AUTOSAR XML (schema 00046)
package /Composit_SW_Lab
  sender receiver interface SRIF_LightControl
    data Light_Control: type=uint32
  sender receiver interface SRIF_LightActuate
    data Light_Actuate: type=uint32
  sensor actuator sw component type LightControl_SWC
    provide port PP_LightControl: provided-interface=SRIF_LightControl
  sensor actuator sw component type LightActuate_SWC
    require port RP_LightActuate: required-interface=SRIF_LightActuate
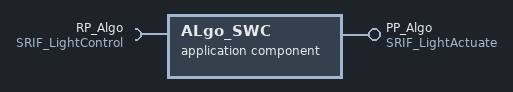
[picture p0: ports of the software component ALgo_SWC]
  application sw component type ALgo_SWC
    provide port PP_Algo: provided-interface=SRIF_LightActuate
    require port RP_Algo: required-interface=SRIF_LightControl
  composition sw component type Composite_SWC1
    provide port PP_Algo_Comp: provided-interface=SRIF_LightActuate
    component SA_LC_SWC: type=LightControl_SWC
    component APP_Algo_SWC: type=ALgo_SWC
    connect SA_LC_SWC.PP_LightControl -> APP_Algo_SWC.RP_Algo
    delegate APP_Algo_SWC.PP_Algo <-> outer port PP_Algo_Comp
  composition sw component type Composite2_SWC
    require port RP_LightActuate_Comp2: required-interface=SRIF_LightActuate
    component Composite_inst1_SWC: type=Composite_SWC1
    component SA_LA_SWC: type=LightActuate_SWC
    connect Composite_inst1_SWC.PP_Algo_Comp -> SA_LA_SWC.RP_LightActuate
